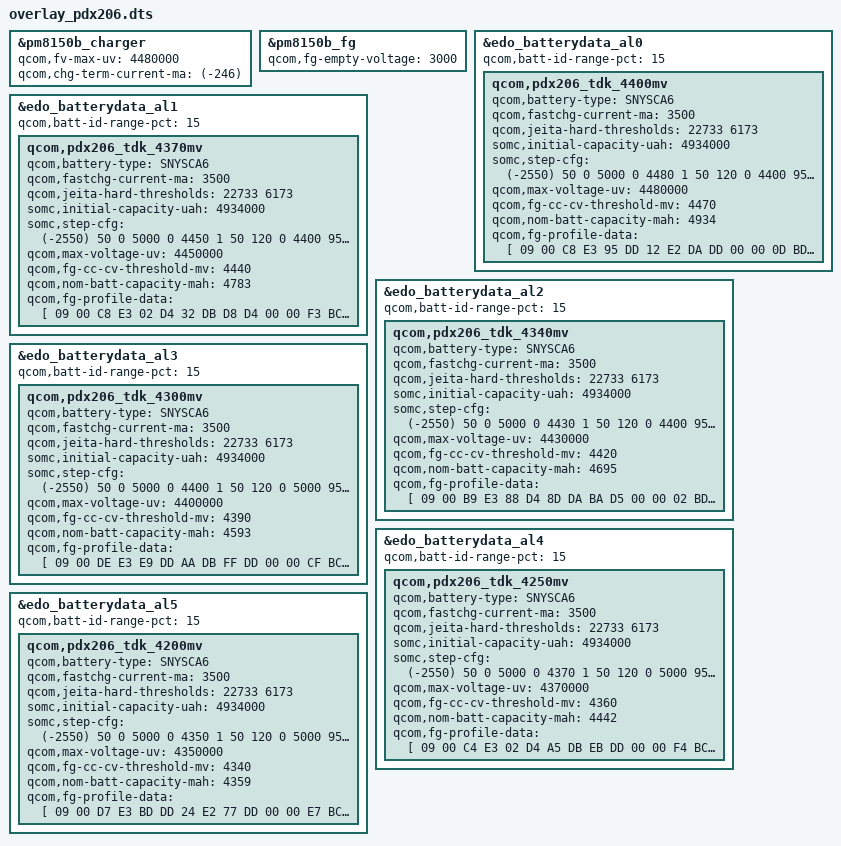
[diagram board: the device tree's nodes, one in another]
/dts-v1/;
/plugin/;

&pm8150b_charger {
	qcom,fv-max-uv = <4480000>;
	qcom,chg-term-current-ma = <(-246)>;
};
&pm8150b_fg {
	qcom,fg-empty-voltage = <3000>;
};
&edo_batterydata_al0 {
	qcom,batt-id-range-pct = <15>;
	qcom,pdx206_tdk_4400mv {
		qcom,battery-type = "SNYSCA6";
		qcom,fastchg-current-ma = <3500>;
		qcom,jeita-hard-thresholds = <22733 6173>;
		somc,initial-capacity-uah = <4934000>;
		somc,step-cfg = <
			(-2550)  50    0 5000    0 4480 1
			    50  120    0 4400  950 4480 2
			    50  120 4400 5000  700 4480 2
			   120  150    0 4150 2450 4480 3
			   120  150 4150 4250 1950 4480 3
			   120  150 4250 4350 1450 4480 3
			   120  150 4350 5000  950 4480 3
			   150  200    0 4150 2950 4480 3
			   150  200 4150 4250 2450 4480 3
			   150  200 4250 4350 1950 4480 3
			   150  200 4350 5000 1450 4480 3
			   200  350    0 4250 3500 4480 3
			   200  350 4250 4300 3500 4480 3
			   200  350 4300 4400 2450 4480 3
			   200  350 4400 5000 1700 4480 3
			   350  450    0 4250 3500 4480 3
			   350  450 4250 4300 3500 4480 3
			   350  450 4300 4400 2450 4480 3
			   350  450 4400 5000 1700 4480 3
			   450  550    0 5000 1450 4200 4
			   550 2550    0 5000    0 4200 5
		>;
		qcom,max-voltage-uv = <4480000>;
		qcom,fg-cc-cv-threshold-mv = <4470>;
		qcom,nom-batt-capacity-mah = <4934>;
		qcom,fg-profile-data = [
			 09 00 C8 E3
			 95 DD 12 E2
			 DA DD 00 00
			 0D BD 06 8B
			 FA 87 B6 8B
			 AD 9D 5B 80
			 1D 00 49 FA
			 AC 12 77 FD
			 13 BD CE 07
			 32 00 F3 EA
			 B4 07 EA CB
			 2C 0B 14 E5
			 62 C4 9E 02
			 FE F3 14 D3
			 60 00 4B 00
			 4B 00 47 00
			 29 00 34 00
			 3B 00 41 00
			 41 00 41 00
			 3F 00 60 00
			 34 00 42 00
			 4C 00 44 00
			 3E 00 93 00
			 5E 64 4D 00
			 41 00 42 00
			 60 F0 50 00
			 4E 00 75 10
			 59 10 4C 00
			 9E 28 6D 48
			 58 60 4B 0D
			 4C 00 D8 00
			 14 1F 40 06
			 9A 03 95 04
			 93 1C 3A 0B
			 9A 0D B5 22
			 42 18 19 42
			 88 5D 04 02
			 60 10 AF 1E
			 BD FE 05 03
			 54 F7 D2 1C
			 4D 02 F9 04
			 84 03 70 18
			 55 23 E3 44
			 01 52 64 11
			 EB 1E EF E4
			 74 CB 63 CC
			 DA 1C AA C1
			 DA 04 A4 BB
			 5A 18 31 93
			 2B 85 72 93
			 7C 90 09 80
			 89 F3 7C 05
			 18 FB BB 04
			 00 F8 B6 D4
			 3B DA F0 07
			 68 D3 98 BD
			 13 10 18 D8
			 F1 CD 7C 03
			 ED 04 C5 00
			 CE 07 32 00
			 D1 02 B5 02
			 B3 05 8A 01
			 33 02 CF 04
			 8C 03 C2 03
			 D6 02 46 00
			 3D 00 4D 00
			 50 64 54 00
			 51 00 4F 08
			 54 00 52 00
			 54 00 68 08
			 37 08 45 00
			 56 28 54 48
			 60 60 72 0C
			 49 00 5B 00
			 5D 08 60 00
			 52 00 43 00
			 4B 10 55 10
			 4E 00 63 28
			 7B 48 45 60
			 59 0C 62 00
			 62 F8 47 00
			 D8 00 36 20
			 72 05 48 0A
			 96 0E F7 1C
			 E3 22 33 44
			 D4 5B 7E 18
			 3D 02 3D 05
			 59 02 72 0F
			 3F 0A 9E 1F
			 CD 05 36 02
			 A2 06 D0 1C
			 EF 02 FB 05
			 34 02 7B 18
			 2C 02 53 05
			 46 02 69 00
			 F2 1E FD 04
			 85 03 06 07
			 DB 1C 5F 02
			 F7 04 77 03
			 A8 18 67 03
			 9F 04 50 02
			 67 00 0B 01
			 C0 00 FA 00
			 46 13 00 00
		];
	};
};
&edo_batterydata_al1 {
	qcom,batt-id-range-pct = <15>;
	qcom,pdx206_tdk_4370mv {
		qcom,battery-type = "SNYSCA6";
		qcom,fastchg-current-ma = <3500>;
		qcom,jeita-hard-thresholds = <22733 6173>;
		somc,initial-capacity-uah = <4934000>;
		somc,step-cfg = <
			(-2550)  50    0 5000    0 4450 1
			    50  120    0 4400  950 4450 2
			    50  120 4400 5000  700 4450 2
			   120  150    0 4150 2450 4450 3
			   120  150 4150 4250 1950 4450 3
			   120  150 4250 4350 1450 4450 3
			   120  150 4350 5000  950 4450 3
			   150  200    0 4150 2700 4450 3
			   150  200 4150 4250 2200 4450 3
			   150  200 4250 4350 1950 4450 3
			   150  200 4350 5000 1450 4450 3
			   200  350    0 4200 3500 4450 3
			   200  350 4200 4250 3400 4450 3
			   200  350 4250 4350 2200 4450 3
			   200  350 4350 5000 1450 4450 3
			   350  450    0 4200 3500 4450 3
			   350  450 4200 4250 3400 4450 3
			   350  450 4250 4350 2200 4450 3
			   350  450 4350 5000 1450 4450 3
			   450  550    0 5000 1450 4200 4
			   550 2550    0 5000    0 4200 5
		>;
		qcom,max-voltage-uv = <4450000>;
		qcom,fg-cc-cv-threshold-mv = <4440>;
		qcom,nom-batt-capacity-mah = <4783>;
		qcom,fg-profile-data = [
			 09 00 C8 E3
			 02 D4 32 DB
			 D8 D4 00 00
			 F3 BC F1 8A
			 FB 87 24 8B
			 2C 9D 72 80
			 22 00 B6 01
			 95 12 94 06
			 47 E2 CE 07
			 32 00 6F EB
			 5B ED 0D C4
			 B6 0B EB E4
			 CD CD 56 EB
			 49 01 DB D2
			 60 00 4D 00
			 47 00 46 00
			 2D 00 35 00
			 3B 00 3D 00
			 41 00 41 00
			 40 00 60 00
			 2C 00 3C 00
			 46 00 40 00
			 39 00 88 00
			 5A 64 49 00
			 3D 00 39 00
			 60 F8 4E 00
			 4B 00 6D 10
			 58 10 49 00
			 A6 28 6C 48
			 57 60 49 0C
			 47 00 D8 F8
			 37 1F 12 06
			 D5 F3 FF 05
			 7B 1C 7C 0B
			 64 0D E4 22
			 02 18 59 42
			 00 55 A8 02
			 61 11 CF 1E
			 2B FD 37 03
			 CA FC D6 1C
			 3B FA 1F 05
			 48 03 B0 18
			 FC 22 61 45
			 2E 53 68 11
			 2C 1F 57 E4
			 D7 C3 C3 B5
			 D8 1C 53 BB
			 DB 04 89 BB
			 39 18 47 93
			 17 85 8A 9B
			 80 98 09 80
			 A2 EB 8D 04
			 72 FB 84 F2
			 00 F8 89 DC
			 4F E2 F0 FF
			 84 E2 77 CD
			 1C 10 19 00
			 F5 DD E3 03
			 EB 04 09 03
			 CE 07 32 00
			 FB 02 37 02
			 BE 04 89 02
			 34 04 59 02
			 A2 03 99 01
			 49 05 44 00
			 3C 00 4D 00
			 51 64 55 00
			 52 00 51 00
			 53 00 51 00
			 53 00 5E 08
			 34 08 44 00
			 56 28 53 48
			 5E 60 6F 0D
			 48 00 59 00
			 61 08 66 00
			 6F 00 41 00
			 4A 08 55 08
			 4E 00 61 28
			 7A 48 45 60
			 56 0D 61 00
			 61 F8 46 08
			 D8 F8 04 20
			 BF 05 FD 0B
			 D9 0E F9 1C
			 D3 22 58 44
			 9E 5B 87 18
			 25 02 76 05
			 14 02 73 0F
			 3F 0A 42 20
			 13 05 B4 02
			 27 06 D9 1C
			 B9 02 79 04
			 A9 03 83 18
			 17 02 86 05
			 06 02 74 00
			 43 1F 31 04
			 0D 02 69 05
			 D8 1C 57 02
			 16 05 39 03
			 A6 18 65 03
			 A1 04 50 02
			 6D 00 03 01
			 C0 00 FA 00
			 AF 12 00 00
		];
	};
};
&edo_batterydata_al2 {
	qcom,batt-id-range-pct = <15>;
	qcom,pdx206_tdk_4340mv {
		qcom,battery-type = "SNYSCA6";
		qcom,fastchg-current-ma = <3500>;
		qcom,jeita-hard-thresholds = <22733 6173>;
		somc,initial-capacity-uah = <4934000>;
		somc,step-cfg = <
			(-2550)  50    0 5000    0 4430 1
			    50  120    0 4400  950 4430 2
			    50  120 4400 5000  700 4430 2
			   120  150    0 4150 2200 4430 3
			   120  150 4150 4250 1700 4430 3
			   120  150 4250 4350 1450 4430 3
			   120  150 4350 5000  950 4430 3
			   150  200    0 4150 2700 4430 3
			   150  200 4150 4250 2200 4430 3
			   150  200 4250 4350 1950 4430 3
			   150  200 4350 5000 1200 4430 3
			   200  350    0 4200 3500 4430 3
			   200  350 4200 4250 3400 4430 3
			   200  350 4250 4350 2200 4430 3
			   200  350 4350 5000 1450 4430 3
			   350  450    0 4200 3500 4430 3
			   350  450 4200 4250 3400 4430 3
			   350  450 4250 4350 2200 4430 3
			   350  450 4350 5000 1450 4430 3
			   450  550    0 5000 1450 4200 4
			   550 2550    0 5000    0 4200 5
		>;
		qcom,max-voltage-uv = <4430000>;
		qcom,fg-cc-cv-threshold-mv = <4420>;
		qcom,nom-batt-capacity-mah = <4695>;
		qcom,fg-profile-data = [
			 09 00 B9 E3
			 88 D4 8D DA
			 BA D5 00 00
			 02 BD F3 8A
			 FB 87 F5 9A
			 04 9C 55 80
			 1E 00 3F 01
			 64 12 DF FD
			 96 E4 CE 07
			 32 00 15 EB
			 72 ED 43 D2
			 AF 0B 9D E5
			 13 C4 C1 0C
			 47 DA CD D2
			 60 00 4D 00
			 4C 00 49 00
			 2C 00 35 00
			 3B 00 41 00
			 45 00 40 00
			 3E 00 60 00
			 33 00 42 00
			 4C 00 46 00
			 3D 00 8B 00
			 62 64 4E 00
			 40 00 3E 08
			 60 00 50 00
			 4B 00 6C 08
			 5B 08 49 00
			 A7 20 6E 40
			 59 58 4A 0E
			 44 00 D8 00
			 AC 1F 93 0D
			 40 02 A7 FE
			 AE 1C C0 02
			 48 04 EA 23
			 67 18 B7 43
			 11 54 E1 02
			 6F 11 34 21
			 1A FC 3D 03
			 C4 F5 F7 1C
			 29 03 08 05
			 31 0B 44 18
			 6B 23 DE 44
			 EC 53 94 11
			 DA 1E 0F E5
			 44 C3 77 BC
			 C8 1C D5 B1
			 3F 04 0C BA
			 49 18 33 93
			 2B 85 71 9B
			 78 98 09 80
			 98 EB 6F 04
			 28 02 EF F3
			 00 F8 8D D4
			 62 E2 EE 07
			 FC E3 30 C5
			 FC 17 18 00
			 49 DD A5 03
			 5C 06 A1 03
			 CE 07 32 00
			 F9 02 D9 02
			 F4 05 0C 03
			 4B 04 A2 02
			 67 02 5D 01
			 FC 05 44 00
			 3C 00 4D 00
			 50 64 54 00
			 52 00 50 00
			 53 F0 53 00
			 53 00 4F 10
			 37 10 43 00
			 55 28 53 48
			 5E 60 6F 0C
			 4A 00 52 00
			 5C 08 5C 00
			 4D 00 41 00
			 49 10 56 10
			 4F 00 5F 28
			 7A 48 47 60
			 52 0C 5C 00
			 5C 00 41 08
			 D8 F8 A7 1F
			 2B 06 54 0B
			 93 0C E4 1C
			 0E 23 F3 45
			 0E 5A 7B 18
			 37 02 47 05
			 51 02 6C 10
			 3F 0A A9 1F
			 C6 05 2B 02
			 9F 06 BB 1C
			 22 03 D1 05
			 50 02 78 18
			 25 02 5E 05
			 3D 02 69 00
			 AC 1F AA 05
			 51 02 E1 04
			 E1 1C 22 02
			 8D 05 9C 02
			 AB 18 4B 03
			 D3 04 1C 02
			 78 00 03 01
			 C0 00 FA 00
			 57 12 00 00
		];
	};
};
&edo_batterydata_al3 {
	qcom,batt-id-range-pct = <15>;
	qcom,pdx206_tdk_4300mv {
		qcom,battery-type = "SNYSCA6";
		qcom,fastchg-current-ma = <3500>;
		qcom,jeita-hard-thresholds = <22733 6173>;
		somc,initial-capacity-uah = <4934000>;
		somc,step-cfg = <
			(-2550)  50    0 5000    0 4400 1
			    50  120    0 5000  950 4400 2
			   120  150    0 4150 1950 4400 3
			   120  150 4150 4250 1450 4400 3
			   120  150 4250 5000  950 4400 3
			   150  200    0 4100 2450 4400 3
			   150  200 4100 4200 1950 4400 3
			   150  200 4200 4300 1700 4400 3
			   150  200 4300 5000  950 4400 3
			   200  350    0 4150 3500 4400 3
			   200  350 4150 4200 2950 4400 3
			   200  350 4200 4300 1700 4400 3
			   200  350 4300 5000 1200 4400 3
			   350  450    0 4150 3500 4400 3
			   350  450 4150 4200 2950 4400 3
			   350  450 4200 4300 1700 4400 3
			   350  450 4300 5000 1200 4400 3
			   450  550    0 5000 1450 4200 4
			   550 2550    0 5000    0 4200 5
		>;
		qcom,max-voltage-uv = <4400000>;
		qcom,fg-cc-cv-threshold-mv = <4390>;
		qcom,nom-batt-capacity-mah = <4593>;
		qcom,fg-profile-data = [
			 09 00 DE E3
			 E9 DD AA DB
			 FF DD 00 00
			 CF BC 1F 8B
			 FB 87 90 82
			 A1 94 66 80
			 20 00 39 FB
			 63 12 07 F4
			 71 ED CE 07
			 32 00 2F EB
			 45 ED D6 D2
			 83 0B 9D E5
			 4D C4 CF 04
			 AC 00 3D D2
			 60 00 4D 00
			 4C 00 4B 00
			 33 00 35 00
			 39 00 42 00
			 4D 00 41 00
			 3B 00 60 00
			 33 00 43 00
			 49 00 46 00
			 3B 00 64 00
			 63 64 50 00
			 40 00 37 08
			 60 F8 50 00
			 4C 00 5E 08
			 5F 08 48 00
			 88 20 73 48
			 58 58 4A 0E
			 42 00 D8 08
			 E9 1F 55 0D
			 5D 02 0F 05
			 9E 1C D4 02
			 3F 04 CE 23
			 80 18 B6 43
			 F8 55 14 03
			 73 11 8D 22
			 69 05 FE 03
			 1F 05 FA 1C
			 82 F9 47 05
			 D5 02 3C 18
			 59 23 05 45
			 A1 53 A0 13
			 83 1F E3 E5
			 FD C3 CB B6
			 DE 1C 0D BB
			 50 05 E1 BA
			 5B 18 F2 92
			 98 85 B3 9A
			 8B 98 09 80
			 B8 03 A0 04
			 A0 FA 61 F2
			 00 F8 4B DC
			 95 E2 ED 07
			 DD EA CD D5
			 0F 10 18 00
			 D0 E7 A3 03
			 CF 04 79 03
			 CE 07 32 00
			 29 03 49 03
			 12 04 AE 02
			 94 04 4A 02
			 20 02 CB 02
			 A7 04 46 00
			 3C 00 4F 00
			 52 64 55 00
			 55 F8 53 00
			 53 F0 55 00
			 56 00 4C 08
			 37 08 42 00
			 56 28 54 48
			 5D 60 6E 0D
			 52 00 4E 00
			 5A 08 64 00
			 54 00 42 00
			 47 08 55 08
			 52 00 5C 20
			 78 48 5F 58
			 4E 0E 5D 00
			 63 F8 4D 00
			 D8 F8 78 1F
			 E7 04 CC 0A
			 75 0D E1 1C
			 08 23 00 44
			 EF 53 83 18
			 1D 02 81 05
			 0A 02 6C 10
			 3F 0A 97 20
			 C6 04 D2 02
			 00 06 D7 1C
			 A0 02 BB 04
			 3A 03 94 18
			 D2 03 E7 05
			 30 03 7B 00
			 62 1F 09 04
			 FF 03 6D 05
			 D1 1C 52 02
			 31 05 F1 02
			 B0 18 26 03
			 12 05 C5 03
			 72 00 08 01
			 C0 00 FA 00
			 F1 11 00 00
		];
	};
};
&edo_batterydata_al4 {
	qcom,batt-id-range-pct = <15>;
	qcom,pdx206_tdk_4250mv {
		qcom,battery-type = "SNYSCA6";
		qcom,fastchg-current-ma = <3500>;
		qcom,jeita-hard-thresholds = <22733 6173>;
		somc,initial-capacity-uah = <4934000>;
		somc,step-cfg = <
			(-2550)  50    0 5000    0 4370 1
			    50  120    0 5000  950 4370 2
			   120  150    0 4150 1950 4370 3
			   120  150 4150 4250 1450 4370 3
			   120  150 4250 5000  950 4370 3
			   150  200    0 4100 2450 4370 3
			   150  200 4100 4200 1950 4370 3
			   150  200 4200 4300 1700 4370 3
			   150  200 4300 5000  950 4370 3
			   200  350    0 4150 3500 4370 3
			   200  350 4150 4200 2950 4370 3
			   200  350 4200 4300 1700 4370 3
			   200  350 4300 5000 1200 4370 3
			   350  450    0 4150 3500 4370 3
			   350  450 4150 4200 2950 4370 3
			   350  450 4200 4300 1700 4370 3
			   350  450 4300 5000 1200 4370 3
			   450  550    0 5000 1450 4200 4
			   550 2550    0 5000    0 4200 5
		>;
		qcom,max-voltage-uv = <4370000>;
		qcom,fg-cc-cv-threshold-mv = <4360>;
		qcom,nom-batt-capacity-mah = <4442>;
		qcom,fg-profile-data = [
			 09 00 C4 E3
			 02 D4 A5 DB
			 EB DD 00 00
			 F4 BC 08 8B
			 FA 87 8C 8D
			 17 95 7A 80
			 23 00 24 02
			 5B 12 70 06
			 25 EA CE 07
			 32 00 FD EB
			 EE EC EF C2
			 66 12 1B E5
			 61 CD FA 0D
			 19 FA FB CB
			 60 00 41 00
			 40 00 40 00
			 3B 00 31 00
			 38 00 48 00
			 42 00 3F 00
			 41 00 60 00
			 26 00 34 00
			 41 00 42 00
			 37 00 3B 00
			 59 64 44 00
			 39 00 33 08
			 60 00 50 00
			 4C 00 49 08
			 64 08 48 00
			 4E 20 73 40
			 56 58 47 0E
			 40 00 D8 F8
			 39 20 18 05
			 6C F2 7A 06
			 A0 1C AB 0A
			 AB 0C 33 23
			 7C 18 98 43
			 32 54 C9 02
			 7C 12 1F 1F
			 B1 0C 31 13
			 8F 04 D2 1C
			 0B 02 A4 05
			 66 FA 6E 18
			 0F 23 61 45
			 18 53 77 13
			 91 24 9C E4
			 62 C2 8E A4
			 E6 1C 48 B9
			 38 06 B1 BB
			 5C 18 F3 92
			 95 85 B7 9A
			 B6 98 09 80
			 A2 BB 25 0D
			 A2 05 29 F3
			 00 00 7D E4
			 6F 02 EE 07
			 EF E2 3A BD
			 1F 00 18 E8
			 DE C2 00 02
			 60 06 49 03
			 CE 07 32 00
			 9C 01 23 02
			 BC 07 E6 02
			 85 03 40 04
			 6B 03 56 04
			 91 05 45 00
			 3C 00 50 00
			 51 64 55 00
			 56 00 52 00
			 52 E8 55 00
			 53 00 44 08
			 36 08 40 00
			 55 20 52 48
			 5A 58 69 0E
			 70 00 49 00
			 5C 08 63 00
			 4C 00 43 00
			 46 08 54 08
			 55 00 59 20
			 75 40 73 58
			 48 0F 5A 00
			 62 00 52 08
			 D8 F8 86 1F
			 8E 06 5A 0A
			 D5 0C F3 1C
			 A4 22 DB 44
			 DA 52 93 18
			 EB 03 D9 05
			 45 03 79 11
			 3F 0A 68 21
			 00 04 3E 03
			 A1 05 E8 1C
			 54 02 4F 05
			 87 02 AF 18
			 6B 03 9B 04
			 54 02 88 00
			 2D 20 3E 05
			 6E 02 A5 04
			 DF 1C 00 02
			 DE 05 14 02
			 B8 18 F9 02
			 62 05 2E 03
			 85 00 07 01
			 C0 00 FA 00
			 5A 11 00 00
		];
	};
};
&edo_batterydata_al5 {
	qcom,batt-id-range-pct = <15>;
	qcom,pdx206_tdk_4200mv {
		qcom,battery-type = "SNYSCA6";
		qcom,fastchg-current-ma = <3500>;
		qcom,jeita-hard-thresholds = <22733 6173>;
		somc,initial-capacity-uah = <4934000>;
		somc,step-cfg = <
			(-2550)  50    0 5000    0 4350 1
			    50  120    0 5000  950 4350 2
			   120  150    0 4150 1950 4350 3
			   120  150 4150 4250 1450 4350 3
			   120  150 4250 5000  950 4350 3
			   150  200    0 4100 2450 4350 3
			   150  200 4100 4200 1950 4350 3
			   150  200 4200 4300 1700 4350 3
			   150  200 4300 5000  950 4350 3
			   200  350    0 4150 3500 4350 3
			   200  350 4150 4200 2950 4350 3
			   200  350 4200 4300 1700 4350 3
			   200  350 4300 5000 1200 4350 3
			   350  450    0 4150 3500 4350 3
			   350  450 4150 4200 2950 4350 3
			   350  450 4200 4300 1700 4350 3
			   350  450 4300 5000 1200 4350 3
			   450  550    0 5000 1450 4200 4
			   550 2550    0 5000    0 4200 5
		>;
		qcom,max-voltage-uv = <4350000>;
		qcom,fg-cc-cv-threshold-mv = <4340>;
		qcom,nom-batt-capacity-mah = <4359>;
		qcom,fg-profile-data = [
			 09 00 D7 E3
			 BD DD 24 E2
			 77 DD 00 00
			 E7 BC 13 8B
			 FA 87 91 95
			 E3 95 81 80
			 25 00 49 02
			 6F 12 65 06
			 4E 00 CE 07
			 32 00 16 F2
			 A7 EC 73 C3
			 2B 12 9B DC
			 D4 CD EF F5
			 53 FA 14 CA
			 60 00 42 00
			 42 00 41 00
			 41 00 27 00
			 35 00 41 00
			 3B 00 44 00
			 2E 00 60 00
			 27 00 36 00
			 42 00 45 00
			 39 00 34 00
			 5D 64 43 00
			 39 00 32 08
			 60 00 55 00
			 4E 00 49 08
			 6D 08 4E 00
			 44 20 7B 40
			 56 58 47 0F
			 41 00 D8 00
			 4E 20 26 05
			 3D 02 AD 06
			 9B 1C 93 02
			 F0 04 CB 22
			 8B 18 69 43
			 83 54 78 02
			 83 13 D7 1F
			 A7 05 F6 0B
			 CA 06 D8 1C
			 DF 01 0D 04
			 BC 03 77 18
			 E2 22 A9 45
			 9E 52 88 14
			 73 20 0B E5
			 63 C2 6B CE
			 D1 1C 88 C1
			 62 05 79 BA
			 55 18 C9 92
			 D7 85 4C 92
			 9B 80 09 80
			 9D 03 73 04
			 4C 02 FF 04
			 00 F8 73 E4
			 78 EA EE EF
			 31 04 75 C7
			 60 10 1A C8
			 10 E0 C8 03
			 7A 06 CA 00
			 CE 07 32 00
			 69 03 B8 03
			 77 04 A4 02
			 87 00 D8 05
			 74 02 69 05
			 BB 05 46 00
			 3B 00 4F 00
			 51 64 54 00
			 57 E8 54 E8
			 55 E8 54 00
			 53 00 45 08
			 35 08 3D 00
			 55 20 50 48
			 58 58 65 0E
			 75 00 46 00
			 56 08 6B 00
			 5A 00 3D 00
			 40 08 51 08
			 53 00 50 20
			 6B 40 7C 58
			 40 0F 50 00
			 63 00 59 00
			 D8 F8 9D 1E
			 E5 05 4D 0B
			 E9 0B DD 1C
			 CF 22 9F 44
			 0B 53 81 18
			 E9 03 DB 05
			 42 03 6D 12
			 3F 0A C2 20
			 D0 04 92 02
			 3A 06 D3 1C
			 78 02 25 05
			 95 02 A5 18
			 65 03 A3 04
			 4E 02 85 00
			 5E 1F 30 06
			 60 03 F1 05
			 CA 1C 36 02
			 81 05 64 02
			 B9 18 DA 02
			 93 05 DD 02
			 7B 00 0B 01
			 C0 00 FA 00
			 07 11 00 00
		];
	};
};
